# mc200 register map
Registers from a debugger description file.
Registers are 32-bit, access not given, no defined reset value unless marked. A register's access mark holds for its fields unless they carry their own. Addresses are absolute; registers are grouped by the start of their names; lines under a group give offsets from that group; [hi:lo] are bit positions; {n}, {i} and the like mark numbered series; 'fields as' and 'values as' point back to an identical list; <NAME> marks a mode.

## DMAC
{0x44000000+0x58*i} DMAC_SAR{i} 64-bit (i=0..7)
  [31:0] SAR
{0x44000008+0x58*i} DMAC_DAR{i} 64-bit (i=0..7)
  [31:0] DAR
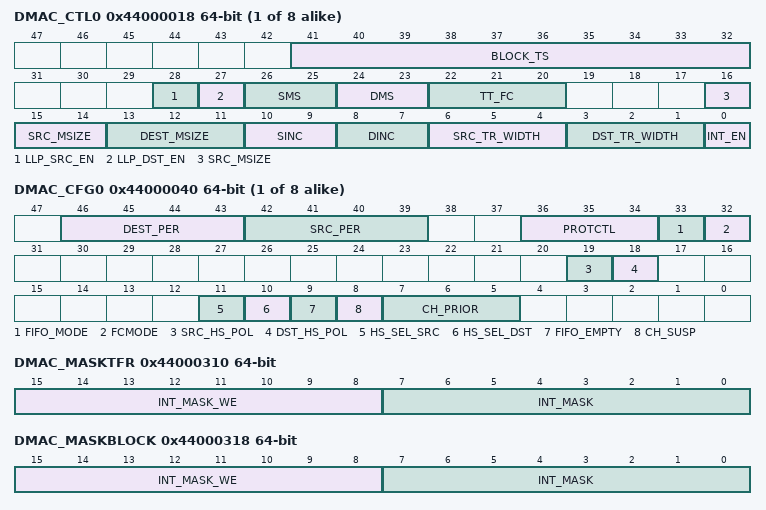
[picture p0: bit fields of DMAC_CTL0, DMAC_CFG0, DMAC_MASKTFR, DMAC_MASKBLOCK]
{0x44000018+0x58*i} DMAC_CTL{i} 64-bit (i=0..7)
  [41:32] BLOCK_TS, [28] LLP_SRC_EN, [27] LLP_DST_EN, [26:25] SMS, [24:23] DMS, [22:20] TT_FC, [16:14] SRC_MSIZE, [13:11] DEST_MSIZE, [10:9] SINC, [8:7] DINC, [6:4] SRC_TR_WIDTH, [3:1] DST_TR_WIDTH, [0] INT_EN
{0x44000040+0x58*i} DMAC_CFG{i} 64-bit (i=0..7)
  [46:43] DEST_PER, [42:39] SRC_PER, [36:34] PROTCTL, [33] FIFO_MODE, [32] FCMODE, [19] SRC_HS_POL, [18] DST_HS_POL, [11] HS_SEL_SRC, [10] HS_SEL_DST, [9] FIFO_EMPTY, [8] CH_SUSP, [7:5] CH_PRIOR
0x440002C0 DMAC_RAWTFR 64-bit
  [7:0] RAW
0x440002C8 DMAC_RAWBLOCK 64-bit
  [7:0] RAW
0x440002D0 DMAC_RAWSRCTRAN 64-bit
  [7:0] RAW
0x440002D8 DMAC_RAWDSTTRAN 64-bit
  [7:0] RAW
0x440002E0 DMAC_RAWERR 64-bit
  [7:0] RAW
0x440002E8 DMAC_STATUSTFR 64-bit
  [7:0] STATUS
0x440002F0 DMAC_STATUSBLOCK 64-bit
  [7:0] STATUS
0x440002F8 DMAC_STATUSSRCTRAN 64-bit
  [7:0] STATUS
0x44000300 DMAC_STATUSDSTTRAN 64-bit
  [7:0] STATUS
0x44000308 DMAC_STATUSERR 64-bit
  [7:0] STATUS
0x44000310 DMAC_MASKTFR 64-bit
  [15:8] INT_MASK_WE, [7:0] INT_MASK
0x44000318 DMAC_MASKBLOCK 64-bit
  [15:8] INT_MASK_WE, [7:0] INT_MASK
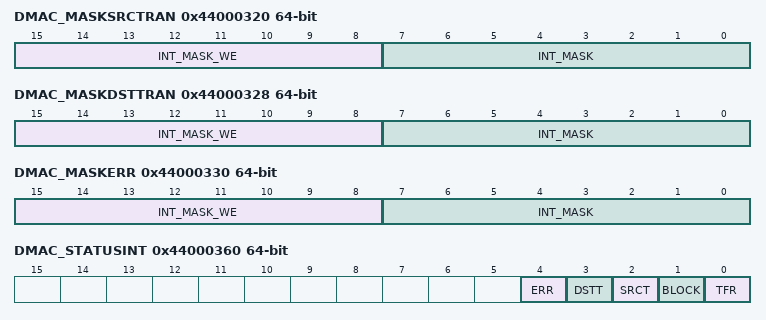
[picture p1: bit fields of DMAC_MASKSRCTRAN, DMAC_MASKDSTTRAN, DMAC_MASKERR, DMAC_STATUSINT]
0x44000320 DMAC_MASKSRCTRAN 64-bit
  [15:8] INT_MASK_WE, [7:0] INT_MASK
0x44000328 DMAC_MASKDSTTRAN 64-bit
  [15:8] INT_MASK_WE, [7:0] INT_MASK
0x44000330 DMAC_MASKERR 64-bit
  [15:8] INT_MASK_WE, [7:0] INT_MASK
0x44000338 DMAC_CLEARTFR 64-bit
  [7:0] CLEAR
0x44000340 DMAC_CLEARBLOCK 64-bit
  [7:0] CLEAR
0x44000348 DMAC_CLEARSRCTRAN 64-bit
  [7:0] CLEAR
0x44000350 DMAC_CLEARDSTTRAN 64-bit
  [7:0] CLEAR
0x44000358 DMAC_CLEARERR 64-bit
  [7:0] CLEAR
0x44000360 DMAC_STATUSINT 64-bit
  [4] ERR, [3] DSTT, [2] SRCT, [1] BLOCK, [0] TFR
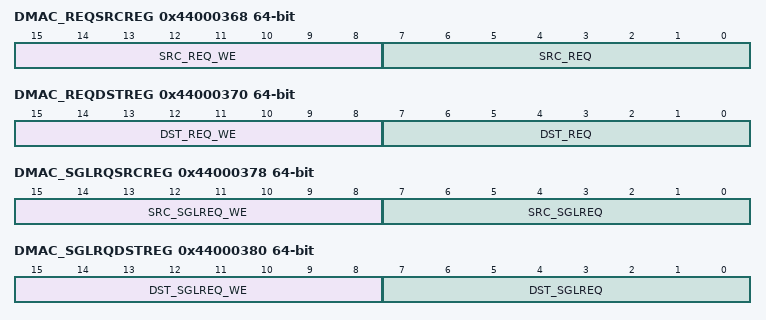
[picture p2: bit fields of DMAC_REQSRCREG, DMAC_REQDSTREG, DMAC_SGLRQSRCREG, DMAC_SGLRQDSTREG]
0x44000368 DMAC_REQSRCREG 64-bit
  [15:8] SRC_REQ_WE, [7:0] SRC_REQ
0x44000370 DMAC_REQDSTREG 64-bit
  [15:8] DST_REQ_WE, [7:0] DST_REQ
0x44000378 DMAC_SGLRQSRCREG 64-bit
  [15:8] SRC_SGLREQ_WE, [7:0] SRC_SGLREQ
0x44000380 DMAC_SGLRQDSTREG 64-bit
  [15:8] DST_SGLREQ_WE, [7:0] DST_SGLREQ
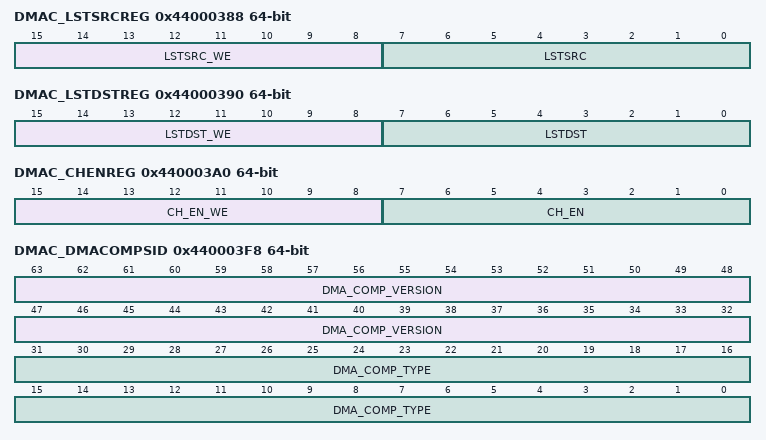
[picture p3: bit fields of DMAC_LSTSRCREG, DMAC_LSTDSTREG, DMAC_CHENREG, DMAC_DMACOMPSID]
0x44000388 DMAC_LSTSRCREG 64-bit
  [15:8] LSTSRC_WE, [7:0] LSTSRC
0x44000390 DMAC_LSTDSTREG 64-bit
  [15:8] LSTDST_WE, [7:0] LSTDST
0x44000398 DMAC_DMACFGREG 64-bit
  [0] DMA_EN
0x440003A0 DMAC_CHENREG 64-bit
  [15:8] CH_EN_WE, [7:0] CH_EN
0x440003A8 DMAC_DMAIDREG 64-bit
  [31:0] DMA_ID
0x440003B0 DMAC_DMATESTREG 64-bit
  [0] TEST_SLV_IF
0x440003F8 DMAC_DMACOMPSID 64-bit
  [63:32] DMA_COMP_VERSION, [31:0] DMA_COMP_TYPE

## USBC
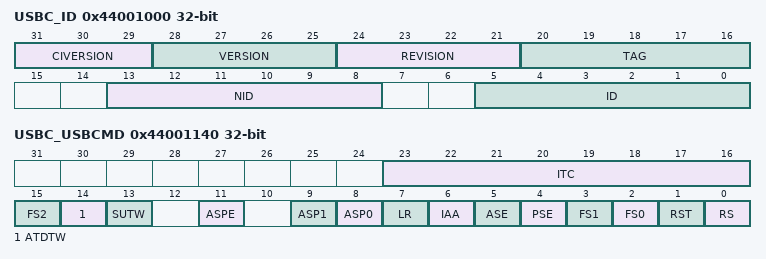
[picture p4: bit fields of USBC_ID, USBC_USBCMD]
0x44001000 USBC_ID
  [31:29] CIVERSION, [28:25] VERSION, [24:21] REVISION, [20:16] TAG, [13:8] NID, [5:0] ID
0x44001004 USBC_HWGENERAL
  [31:0] TBD
0x44001008 USBC_HWHOST
  [31:0] TBD
0x4400100C USBC_HWDEVICE
  [31:0] TBD
0x44001010 USBC_HWTXBUF
  [31:0] TBD
0x44001014 USBC_HWRXBUF
  [31:0] TBD
0x44001080 USBC_GPTIMER0LD
  [31:0] TBD
0x44001084 USBC_GPTIMER0CTRL
  [31:0] TBD
0x44001088 USBC_GPTIMER1LD
  [31:0] TBD
0x4400108C USBC_GPTIMER1CTRL
  [31:0] TBD
0x44001090 USBC_SBUSCFG
  [31:0] TBD
0x44001100 USBC_CAPLENGTH
  [7:0] TBD
0x44001102 USBC_HCIVERSION
  [15:0] TBD
0x44001104 USBC_HCSPARAMS
  [31:0] TBD
0x44001108 USBC_HCCPARAMS
  [31:0] TBD
0x44001120 USBC_DCIVERSION
  [15:0] TBD
0x44001122 USBC_DCCPARAMS
  [31:0] TBD
0x44001140 USBC_USBCMD
  [23:16] ITC, [15] FS2, [14] ATDTW, [13] SUTW, [11] ASPE, [9] ASP1, [8] ASP0, [7] LR, [6] IAA, [5] ASE, [4] PSE, [3] FS1, [2] FS0, [1] RST, [0] RS
0x44001144 USBC_USBSTS
  [31:0] TBD
0x44001148 USBC_USBINTR
  [31:0] TBD
0x4400114C USBC_FRINDEX
  [31:0] TBD
0x44001154 USBC_PERIODICLISTBASE
  [31:0] TBD
0x44001158 USBC_ASYNCLISTADDR
  [31:0] TBD
0x44001160 USBC_BURSTSIZE
  [31:0] TBD
0x44001164 USBC_TXFILLTUNING
  [31:0] TBD
0x4400116C USBC_IC_USB
  [31:0] TBD
0x44001170 USBC_ULPIVIEWPORT
  [31:0] TBD
0x44001178 USBC_ENDPTNAK
  [31:0] TBD
0x4400117C USBC_ENDPTNAKEN
  [31:0] TBD
0x44001180 USBC_CONFIGFLAG
  [31:0] TBD
0x44001184 USBC_PORTSC1
  [31:0] TBD
0x440011A4 USBC_OTGSC
  [31:0] TBD
0x440011A8 USBC_USBMODE
  [31:0] TBD
0x440011AC USBC_ENDPTSETUPSTAT
  [31:0] TBD
0x440011B0 USBC_ENDPTPRIME
  [31:0] TBD
0x440011B4 USBC_ENDPTFLUSH
  [31:0] TBD
0x440011B8 USBC_ENDPTSTATUS
  [31:0] TBD
0x440011BC USBC_ENDPTCOMPLETE
  [31:0] TBD
{0x440011C0+4i} USBC_ENDPTCTRL{i} (i=0..7)
  [31:0] TBD

## Notices in the file
Copyright 2011 Marvell International Ltd.  All rights reserved.
